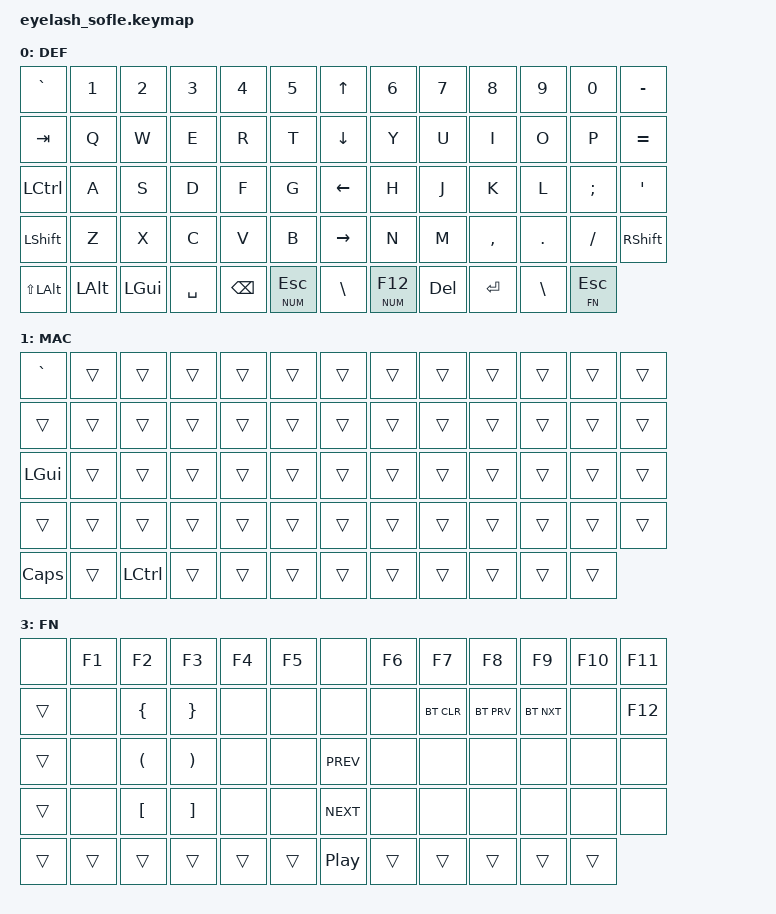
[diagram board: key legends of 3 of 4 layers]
#include <behaviors.dtsi>
#include <dt-bindings/zmk/bt.h>
#include <dt-bindings/zmk/keys.h>
#include <dt-bindings/zmk/mouse.h>
#include <dt-bindings/zmk/outputs.h>
#include <dt-bindings/zmk/rgb.h>

#include <input/processors.dtsi>

// eyelash_sofle.keymap

/*

   &mmv_input_listener {
       input-processors = <&zip_xy_scaler 2 1>;
   };

   &msc_input_listener {
       input-processors = <&zip_xy_scaler 2 1>;
   };

 */

#define ZMK_MOUSE_DEFAULT_MOVE_VAL 1200  // 600
#define ZMK_MOUSE_DEFAULT_SCRL_VAL 20    // 10

#define DEFAULT 0
#define MAC 1
#define NUM 2
#define FN 3


/ {
    behaviors {
        mmv {
            acceleration-exponent = <1>;      // 1
            time-to-max-speed-ms = <900>;    // 40
            delay-ms = <0>;                   // 0
        };

        msc {
            acceleration-exponent = <1>;      // 0
            time-to-max-speed-ms = <400>;      // 500
            delay-ms = <0>;                   //   10
        };
    };

    scroll_encoder: scroll_encoder {
        compatible = "zmk,behavior-sensor-rotate";
        #sensor-binding-cells = <0>;
        bindings = <&msc SCRL_DOWN>, <&msc SCRL_UP>;

        tap-ms = <30>;
    };

    keymap {
        compatible = "zmk,keymap";

        default_layer {
            bindings = <
&kp GRAVE     &kp N1        &kp N2        &kp N3     &kp N4         &kp N5           &kp UP_ARROW     &kp N6       &kp N7     &kp N8     &kp N9        &kp N0      &kp MINUS
&kp TAB       &kp Q         &kp W         &kp E      &kp R          &kp T            &kp DOWN_ARROW   &kp Y        &kp U      &kp I      &kp O         &kp P       &kp EQUAL
&kp LCTRL     &kp A         &kp S         &kp D      &kp F          &kp G            &kp LEFT_ARROW   &kp H        &kp J      &kp K      &kp L         &kp SEMI    &kp SQT
&kp LSHFT     &kp Z         &kp X         &kp C      &kp V          &kp B            &kp RIGHT_ARROW  &kp N        &kp M      &kp COMMA  &kp DOT       &kp FSLH    &kp RSHIFT
&kp LS(LALT)  &kp LEFT_ALT  &kp LEFT_GUI  &kp SPACE  &kp BACKSPACE  &lt NUM ESC      &kp BSLH         &lt NUM F12  &kp DEL    &kp ENTER  &kp BSLH      &lt FN ESC            
            >;

            sensor-bindings = <&inc_dec_kp HOME END>;
            display-name = "DEF";
        };

        mac_layer {
            bindings = <
&kp GRAVE  &trans  &trans     &trans  &trans  &trans       &trans  &trans  &trans  &trans  &trans  &trans  &trans
&trans     &trans  &trans     &trans  &trans  &trans       &trans  &trans  &trans  &trans  &trans  &trans  &trans
&kp LGUI   &trans  &trans     &trans  &trans  &trans       &trans  &trans  &trans  &trans  &trans  &trans  &trans
&trans     &trans  &trans     &trans  &trans  &trans       &trans  &trans  &trans  &trans  &trans  &trans  &trans
&kp CAPS   &trans  &kp LCTRL  &trans  &trans  &trans       &trans  &trans  &trans  &trans  &trans  &trans 
            >;

            display-name = "MAC";
            sensor-bindings = <&inc_dec_kp HOME END>;
        };

        num_layer {
            bindings = <
&none   &none   &none   &none   &none   &none       &kp HOME   &kp KP_NUM  &kp KP_SLASH  &kp KP_ASTERISK  &kp KP_MINUS  &none
&trans  &none   &none   &none   &none   &kp CAPS    &kp END    &kp KP_N7   &kp KP_N8     &kp KP_N9        &kp KP_PLUS   &none
&trans  &none   &none   &none   &none   &kp PSCRN   &kp PG_UP  &kp KP_N4   &kp KP_N5     &kp KP_N6        &kp KP_PLUS   &none
&trans  &none   &none   &none   &none   &none       &kp PG_DN  &kp KP_N1   &kp KP_N2     &kp KP_N3        &kp KP_ENTER  &none
&trans  &trans  &trans  &trans  &trans  &tog MAC    &trans     &trans      &kp KP_N0     &kp KP_DOT       &kp KP_ENTER  &none
         >;

            sensor-bindings = <&scroll_encoder>;
            display-name = "NUM";
        };

        fn_layer {
            bindings = <
&none   &kp F1  &kp F2    &kp F3    &kp F4  &kp F5       &none       &kp F6  &kp F7      &kp F8      &kp F9      &kp F10  &kp F11
&trans  &none   &kp LBRC  &kp RBRC  &none   &none        &none       &none   &bt BT_CLR  &bt BT_PRV  &bt BT_NXT  &none    &kp F12
&trans  &none   &kp LPAR  &kp RPAR  &none   &none        &kp C_PREV  &none   &none       &none       &none       &none    &none
&trans  &none   &kp LBKT  &kp RBKT  &none   &none        &kp C_NEXT  &none   &none       &none       &none       &none    &none
&trans  &trans  &trans    &trans    &trans  &trans       &kp C_PP    &trans  &trans      &trans      &trans      &trans            
            >;

            sensor-bindings = <&scroll_encoder>;
            display-name = "FN";
        };
    };
};
